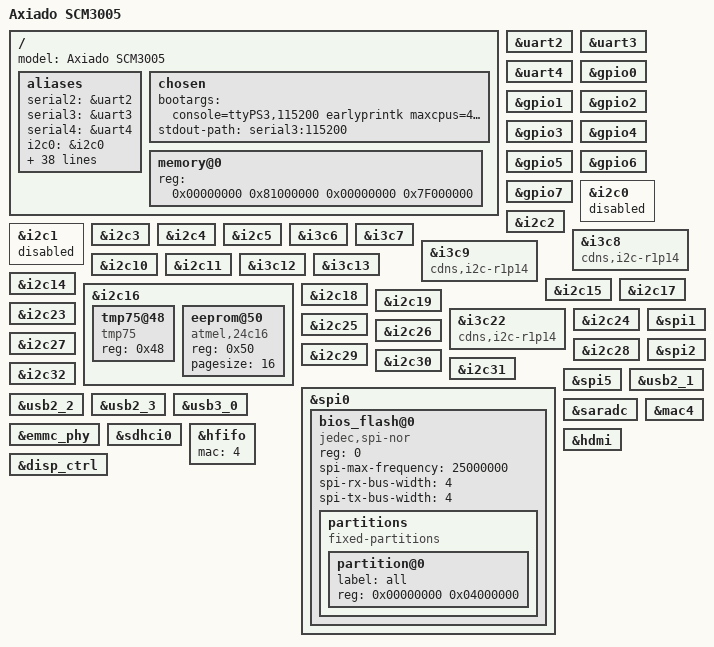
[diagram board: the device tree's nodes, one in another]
// SPDX-License-Identifier: GPL-2.0+
/*
 * DTSI file for Axiado AX3005 soc and SCM3005-mt
 */

/dts-v1/;

#include "ax3005.dtsi"

/ {
	model = "Axiado SCM3005";
	#address-cells = <2>;
	#size-cells = <2>;

	aliases {
		serial2 = &uart2;
		serial3 = &uart3;
		serial4 = &uart4;
		i2c0 = &i2c0;
		i2c1 = &i2c1;
		i2c2 = &i2c2;
		i2c3 = &i2c3;
		i2c4 = &i2c4;
		i2c5 = &i2c5;
		i2c6 = &i3c6;
		i2c7 = &i3c7;
		i2c8 = &i3c8;
		i2c9 = &i3c9;
		i2c10 = &i2c10;
		i2c11 = &i2c11;
		i2c12 = &i3c12;
		i2c13 = &i3c13;
		i2c14 = &i2c14;
		i2c15 = &i2c15;
		i2c16 = &i2c16;
		i2c17 = &i2c17;
		i2c18 = &i2c18;
		i2c19 = &i2c19;
		i2c20 = &i2c20;
		i2c21 = &i2c21;
		i2c22 = &i3c22;
		i2c23 = &i2c23;
		i2c24 = &i2c24;
		i2c25 = &i2c25;
		i2c26 = &i2c26;
		i2c27 = &i2c27;
		i2c28 = &i2c28;
		i2c29 = &i2c29;
		i2c30 = &i2c30;
		i2c31 = &i2c31;
		i2c32 = &i2c32;
		spi0  = &spi0;
		spi1  = &spi1;
		spi2  = &spi2;
		spi3  = &spi3;
		spi5  = &spi5;
		spi6  = &spi6;
	};

	chosen {
		bootargs = "console=ttyPS3,115200 earlyprintk maxcpus=4 nr_cpus=4 earlycon";
		stdout-path = "serial3:115200";
	};

	memory@0 {
		device_type = "memory";
		/* Updates the linux kernel memory map to load from 0x81000000 in DDR */
		reg = <0x00000000 0x81000000 0x00000000 0x7F000000>;
	};
};

&uart2 {
	status = "okay";
};

&uart3 {
	status = "okay";
};

&uart4 {
	status = "okay";
};

&gpio0 {
	status = "okay";
};

&gpio1 {
	status = "okay";
};

&gpio2 {
	status = "okay";
};

&gpio3 {
	status = "okay";
};

&gpio4 {
	status = "okay";
};

&gpio5 {
	status = "okay";
};

&gpio6 {
	status = "okay";
};

&gpio7 {
	status = "okay";
};

/* DC-SCI I2C_BUS12 */
&i2c0 {
	status = "disabled";
};

&i2c1 {
	status = "disabled";
};

/* DC-SCI I2C_BUS13 */
&i2c2 {
	status = "okay";
};

&i2c3 {
	status = "okay";
};

&i2c4 {
	status = "okay";
};

&i2c5 {
	status = "okay";
};

&i3c6 {
	status = "okay";
};

&i3c7 {
	status = "okay";
};

&i3c8 {
	status = "okay";
	/* Let's switch back to i2c */
	compatible = "cdns,i2c-r1p14";
	#address-cells = <1>;
	#size-cells = <0>;
};

&i3c9 {
	status = "okay";
	/* Let's switch back to i2c */
	compatible = "cdns,i2c-r1p14";
	#address-cells = <1>;
	#size-cells = <0>;
};

&i2c10 {
	status = "okay";
};

&i2c11 {
	status = "okay";
};

&i3c12 {
	status = "okay";
};

&i3c13 {
	status = "okay";
};

&i2c14 {
	status = "okay";
};

&i2c15 {
	status = "okay";
};

&i2c16 {
	status = "okay";
	#address-cells = <1>;
	tmp75@48 {
		compatible = "tmp75";
		reg = <0x48>;
		status = "okay";
	};
	eeprom@50 {
		compatible = "atmel,24c16";
		reg = <0x50>;
		pagesize = <16>;
		status = "okay";
	};
};

&i2c17 {
	status = "okay";
};

&i2c18 {
	status = "okay";
};

&i2c19 {
	status = "okay";
};

&i3c22 {
	status = "okay";
	status = "okay";
	/* Let's switch back to i2c */
	compatible = "cdns,i2c-r1p14";
	#address-cells = <1>;
	#size-cells = <0>;
};

&i2c23 {
	status = "okay";
};

&i2c24 {
	status = "okay";
};

&i2c25 {
	status = "okay";
};

&i2c26 {
	status = "okay";
};

&i2c27 {
	status = "okay";
};

&i2c28 {
	status = "okay";
};

&i2c29 {
	status = "okay";
};

&i2c30 {
	status = "okay";
};

&i2c31 {
	status = "okay";
};

&i2c32 {
	status = "okay";
};

&spi0 {
	status = "okay";
	bios_flash@0 {
		status = "okay";
		compatible = "jedec,spi-nor";
		reg = <0>;
		spi-max-frequency = <25000000>;
		spi-rx-bus-width = <4>;
		spi-tx-bus-width = <4>;
		#address-cells = <1>;
		#size-cells = <1>;

		partitions {
			compatible = "fixed-partitions";
			#address-cells = <1>;
			#size-cells = <1>;

			partition@0 {
				label = "all";
				reg = <0x00000000 0x04000000>; // 64MB
			};
		};
	};
};

&spi1 {
	status = "okay";
};

&spi2 {
	status = "okay";
};

&spi5 {
	status = "okay";
};

&usb2_1 {
	status = "okay";
};

&usb2_2 {
	status = "okay";
};

&usb2_3 {
	status = "okay";
};

&usb3_0 {
	status = "okay";
};

&saradc {
	status = "okay";
};

&emmc_phy {
	status = "okay";
};

&sdhci0 {
	status = "okay";
};

&mac4 {
	status = "okay";
};

&hfifo {
	mac = <4>;
	status = "okay";
};

&hdmi {
	status = "okay";
};

&disp_ctrl {
	status = "okay";
};
